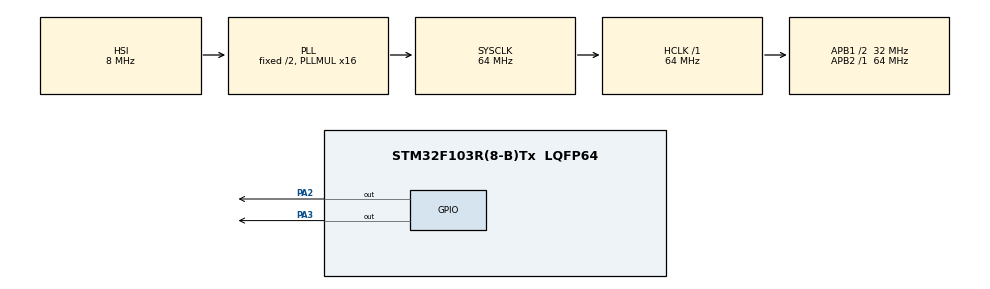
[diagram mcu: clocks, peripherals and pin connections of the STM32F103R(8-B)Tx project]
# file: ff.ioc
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FREERTOS.Tasks01=myTask2,24,128,StartTask02,Default,NULL,Dynamic,NULL,NULL;myTask01,8,128,StartTask01,Default,NULL,Dynamic,NULL,NULL
FREERTOS.configUSE_NEWLIB_REENTRANT=1
Mcu.Family=STM32F1
Mcu.Name=STM32F103R(8-B)Tx
Mcu.Package=LQFP64
NVIC.PriorityGroup=NVIC_PRIORITYGROUP_4
PA13.Mode=Serial_Wire
PA13.Signal=SYS_JTMS-SWDIO
PA14.GPIO_Label=TCK
PA14.Mode=Serial_Wire
PA14.Signal=SYS_JTCK-SWCLK
PA2.Signal=GPIO_Output
PA3.Signal=GPIO_Output
PB3.GPIO_Label=SWO
PB3.Signal=SYS_JTDO-TRACESWO
ProjectManager.HeapSize=0x200
ProjectManager.StackSize=0x400
ProjectManager.TargetToolchain=STM32CubeIDE
RCC.AHBFreq_Value=64000000
RCC.APB1CLKDivider=RCC_HCLK_DIV2
RCC.APB1Freq_Value=32000000
RCC.APB1TimFreq_Value=64000000
RCC.APB2Freq_Value=64000000
RCC.APB2TimFreq_Value=64000000
RCC.HCLKFreq_Value=64000000
RCC.PLLMUL=RCC_PLL_MUL16
RCC.RTCClockSelection=RCC_RTCCLKSOURCE_LSE
RCC.SYSCLKFreq_VALUE=64000000
RCC.SYSCLKSource=RCC_SYSCLKSOURCE_PLLCLK
RCC.USBFreq_Value=64000000
VP_FREERTOS_VS_CMSIS_V2.Mode=CMSIS_V2
board=NUCLEO-F103RB

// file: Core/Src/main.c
/* USER CODE BEGIN Header */
/**
  ******************************************************************************
  * @file           : main.c
  * @brief          : Main program body
  ******************************************************************************
  * @attention
  *
  * Copyright (c) 2025 STMicroelectronics.
  * All rights reserved.
  *
  * This software is licensed under terms that can be found in the LICENSE file
  * in the root directory of this software component.
  * If no LICENSE file comes with this software, it is provided AS-IS.
  *
  ******************************************************************************
  */
/* USER CODE END Header */
#include "main.h"
#include "cmsis_os.h"

/* Definitions for myTask2 */
osThreadId_t myTask2Handle;
const osThreadAttr_t myTask2_attributes = {
  .name = "myTask2",
  .stack_size = 128 * 4,
  .priority = (osPriority_t) osPriorityNormal,
};
/* Definitions for myTask01 */
osThreadId_t myTask01Handle;
const osThreadAttr_t myTask01_attributes = {
  .name = "myTask01",
  .stack_size = 128 * 4,
  .priority = (osPriority_t) osPriorityLow,
};

void SystemClock_Config(void);
static void MX_GPIO_Init(void);
void StartTask02(void *argument);
void StartTask01(void *argument);

int main(void)
{

  /* MCU Configuration--------------------------------------------------------*/

  /* Reset of all peripherals, Initializes the Flash interface and the Systick. */
  HAL_Init();

  /* Configure the system clock */
  SystemClock_Config();

  /* Initialize all configured peripherals */
  MX_GPIO_Init();

  /* Init scheduler */
  osKernelInitialize();

  /* Create the thread(s) */
  /* creation of myTask2 */
  myTask2Handle = osThreadNew(StartTask02, NULL, &myTask2_attributes);

  /* creation of myTask01 */
  myTask01Handle = osThreadNew(StartTask01, NULL, &myTask01_attributes);

  /* Start scheduler */
  osKernelStart();

  /* We should never get here as control is now taken by the scheduler */

  /* Infinite loop */
  while (1)
  {

  }
}

void SystemClock_Config(void)
{
  RCC_OscInitTypeDef RCC_OscInitStruct = {0};
  RCC_ClkInitTypeDef RCC_ClkInitStruct = {0};

  /** Initializes the RCC Oscillators according to the specified parameters
  * in the RCC_OscInitTypeDef structure.
  */
  RCC_OscInitStruct.OscillatorType = RCC_OSCILLATORTYPE_HSI;
  RCC_OscInitStruct.HSIState = RCC_HSI_ON;
  RCC_OscInitStruct.HSICalibrationValue = RCC_HSICALIBRATION_DEFAULT;
  RCC_OscInitStruct.PLL.PLLState = RCC_PLL_ON;
  RCC_OscInitStruct.PLL.PLLSource = RCC_PLLSOURCE_HSI_DIV2;
  RCC_OscInitStruct.PLL.PLLMUL = RCC_PLL_MUL16;
  if (HAL_RCC_OscConfig(&RCC_OscInitStruct) != HAL_OK)
  {
    Error_Handler();
  }

  /** Initializes the CPU, AHB and APB buses clocks
  */
  RCC_ClkInitStruct.ClockType = RCC_CLOCKTYPE_HCLK|RCC_CLOCKTYPE_SYSCLK
                              |RCC_CLOCKTYPE_PCLK1|RCC_CLOCKTYPE_PCLK2;
  RCC_ClkInitStruct.SYSCLKSource = RCC_SYSCLKSOURCE_PLLCLK;
  RCC_ClkInitStruct.AHBCLKDivider = RCC_SYSCLK_DIV1;
  RCC_ClkInitStruct.APB1CLKDivider = RCC_HCLK_DIV2;
  RCC_ClkInitStruct.APB2CLKDivider = RCC_HCLK_DIV1;

  if (HAL_RCC_ClockConfig(&RCC_ClkInitStruct, FLASH_LATENCY_2) != HAL_OK)
  {
    Error_Handler();
  }
}

static void MX_GPIO_Init(void)
{
  GPIO_InitTypeDef GPIO_InitStruct = {0};

  /* GPIO Ports Clock Enable */
  __HAL_RCC_GPIOA_CLK_ENABLE();
  __HAL_RCC_GPIOB_CLK_ENABLE();

  /*Configure GPIO pin Output Level */
  HAL_GPIO_WritePin(GPIOA, GPIO_PIN_2|GPIO_PIN_3, GPIO_PIN_RESET);

  /*Configure GPIO pins : PA2 PA3 */
  GPIO_InitStruct.Pin = GPIO_PIN_2|GPIO_PIN_3;
  GPIO_InitStruct.Mode = GPIO_MODE_OUTPUT_PP;
  GPIO_InitStruct.Pull = GPIO_NOPULL;
  GPIO_InitStruct.Speed = GPIO_SPEED_FREQ_LOW;
  HAL_GPIO_Init(GPIOA, &GPIO_InitStruct);

}

void StartTask02(void *argument)
{
  /* USER CODE BEGIN 5 */
  /* Infinite loop */
  for(;;)
  {
	  HAL_GPIO_TogglePin(GPIOA,GPIO_PIN_3);
    osDelay(500);
  }
  /* USER CODE END 5 */
}

void StartTask01(void *argument)
{
  /* USER CODE BEGIN StartTask01 */
  /* Infinite loop */
  for(;;)
  {
	  HAL_GPIO_TogglePin(GPIOA,GPIO_PIN_2);
    osDelay(1);
  }
  /* USER CODE END StartTask01 */
}

void Error_Handler(void)
{
  __disable_irq();
  while (1)
  {
  }
}
